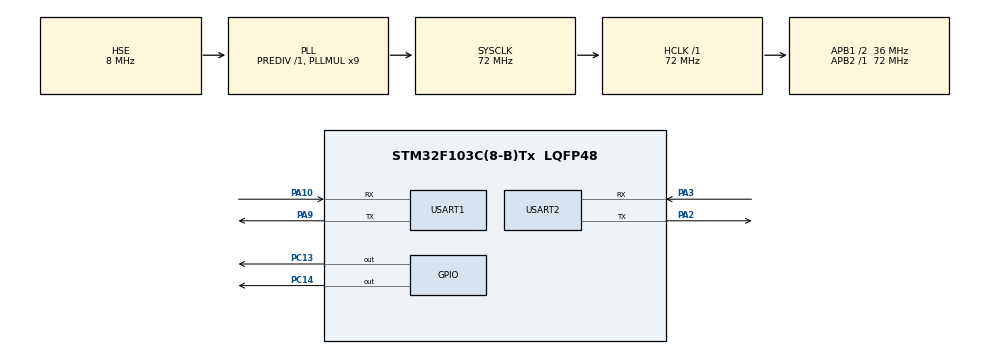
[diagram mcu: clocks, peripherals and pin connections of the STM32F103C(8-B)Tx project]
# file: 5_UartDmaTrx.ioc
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Dma.Request0=USART1_TX
Dma.Request1=USART2_TX
Dma.USART1_TX.0.Direction=DMA_MEMORY_TO_PERIPH
Dma.USART1_TX.0.Instance=DMA1_Channel4
Dma.USART1_TX.0.MemDataAlignment=DMA_MDATAALIGN_BYTE
Dma.USART1_TX.0.MemInc=DMA_MINC_ENABLE
Dma.USART1_TX.0.Mode=DMA_NORMAL
Dma.USART1_TX.0.PeriphDataAlignment=DMA_PDATAALIGN_BYTE
Dma.USART1_TX.0.PeriphInc=DMA_PINC_DISABLE
Dma.USART1_TX.0.Priority=DMA_PRIORITY_MEDIUM
Dma.USART2_TX.1.Direction=DMA_MEMORY_TO_PERIPH
Dma.USART2_TX.1.Instance=DMA1_Channel7
Dma.USART2_TX.1.MemDataAlignment=DMA_MDATAALIGN_BYTE
Dma.USART2_TX.1.MemInc=DMA_MINC_ENABLE
Dma.USART2_TX.1.Mode=DMA_NORMAL
Dma.USART2_TX.1.PeriphDataAlignment=DMA_PDATAALIGN_BYTE
Dma.USART2_TX.1.PeriphInc=DMA_PINC_DISABLE
Dma.USART2_TX.1.Priority=DMA_PRIORITY_MEDIUM
FREERTOS.Tasks01=Task,24,128,Start_Task,Default,NULL,Dynamic,NULL,NULL
Mcu.Family=STM32F1
Mcu.Name=STM32F103C(8-B)Tx
Mcu.Package=LQFP48
NVIC.DMA1_Channel4_IRQn=true\:5\:0\:false\:false\:true\:true\:false\:true\:true
NVIC.DMA1_Channel7_IRQn=true\:5\:0\:false\:false\:true\:true\:false\:true\:true
NVIC.PriorityGroup=NVIC_PRIORITYGROUP_4
NVIC.TIM4_IRQn=true\:15\:0\:false\:false\:true\:false\:false\:true\:true
NVIC.TimeBase=TIM4_IRQn
NVIC.TimeBaseIP=TIM4
NVIC.USART1_IRQn=true\:5\:0\:false\:false\:true\:true\:false\:true\:true
NVIC.USART2_IRQn=true\:5\:0\:false\:false\:true\:true\:true\:true\:true
PA10.Mode=Asynchronous
PA10.Signal=USART1_RX
PA13.Mode=Serial_Wire
PA13.Signal=SYS_JTMS-SWDIO
PA14.Mode=Serial_Wire
PA14.Signal=SYS_JTCK-SWCLK
PA2.Mode=Asynchronous
PA2.Signal=USART2_TX
PA3.Mode=Asynchronous
PA3.Signal=USART2_RX
PA9.Mode=Asynchronous
PA9.Signal=USART1_TX
PC13-TAMPER-RTC.PinState=GPIO_PIN_SET
PC13-TAMPER-RTC.Signal=GPIO_Output
PC14-OSC32_IN.PinState=GPIO_PIN_SET
PC14-OSC32_IN.Signal=GPIO_Output
PD0-OSC_IN.Mode=HSE-External-Oscillator
PD0-OSC_IN.Signal=RCC_OSC_IN
PD1-OSC_OUT.Mode=HSE-External-Oscillator
PD1-OSC_OUT.Signal=RCC_OSC_OUT
ProjectManager.HeapSize=0x200
ProjectManager.StackSize=0x400
ProjectManager.TargetToolchain=MDK-ARM V5.32
RCC.AHBFreq_Value=72000000
RCC.APB1CLKDivider=RCC_HCLK_DIV2
RCC.APB1Freq_Value=36000000
RCC.APB1TimFreq_Value=72000000
RCC.APB2Freq_Value=72000000
RCC.APB2TimFreq_Value=72000000
RCC.EnbaleCSS=true
RCC.HCLKFreq_Value=72000000
RCC.PLLMUL=RCC_PLL_MUL9
RCC.PLLSourceVirtual=RCC_PLLSOURCE_HSE
RCC.SYSCLKFreq_VALUE=72000000
RCC.SYSCLKSource=RCC_SYSCLKSOURCE_PLLCLK
RCC.USBFreq_Value=72000000
USART1.VirtualMode=VM_ASYNC
USART2.VirtualMode=VM_ASYNC
VP_FREERTOS_VS_CMSIS_V2.Mode=CMSIS_V2
VP_SYS_VS_tim4.Mode=TIM4
board=custom

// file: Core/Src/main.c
/* USER CODE BEGIN Header */
/**
  ******************************************************************************
  * @file           : main.c
  * @brief          : Main program body
  ******************************************************************************
  * @attention
  *
  * Copyright (c) 2025 STMicroelectronics.
  * All rights reserved.
  *
  * This software is licensed under terms that can be found in the LICENSE file
  * in the root directory of this software component.
  * If no LICENSE file comes with this software, it is provided AS-IS.
  *
  ******************************************************************************
  */
/* USER CODE END Header */
#include "main.h"
#include "cmsis_os.h"
#include "dma.h"
#include "usart.h"
#include "gpio.h"

/* USER CODE BEGIN PV */

uint8_t tx_buf[64];

/* USER CODE END PV */

void SystemClock_Config(void);
void MX_FREERTOS_Init(void);

int main(void)
{

  /* MCU Configuration--------------------------------------------------------*/

  /* Reset of all peripherals, Initializes the Flash interface and the Systick. */
  HAL_Init();

  /* Configure the system clock */
  SystemClock_Config();

  /* Initialize all configured peripherals */
  MX_GPIO_Init();
  MX_DMA_Init();
  MX_USART1_UART_Init();
  MX_USART2_UART_Init();

  /* Init scheduler */
  osKernelInitialize();  /* Call init function for freertos objects (in cmsis_os2.c) */
  MX_FREERTOS_Init();

  /* Start scheduler */
  osKernelStart();

  /* We should never get here as control is now taken by the scheduler */

  /* Infinite loop */
  while (1)
  {

  }
}

void SystemClock_Config(void)
{
  RCC_OscInitTypeDef RCC_OscInitStruct = {0};
  RCC_ClkInitTypeDef RCC_ClkInitStruct = {0};

  /** Initializes the RCC Oscillators according to the specified parameters
  * in the RCC_OscInitTypeDef structure.
  */
  RCC_OscInitStruct.OscillatorType = RCC_OSCILLATORTYPE_HSE;
  RCC_OscInitStruct.HSEState = RCC_HSE_ON;
  RCC_OscInitStruct.HSEPredivValue = RCC_HSE_PREDIV_DIV1;
  RCC_OscInitStruct.HSIState = RCC_HSI_ON;
  RCC_OscInitStruct.PLL.PLLState = RCC_PLL_ON;
  RCC_OscInitStruct.PLL.PLLSource = RCC_PLLSOURCE_HSE;
  RCC_OscInitStruct.PLL.PLLMUL = RCC_PLL_MUL9;
  if (HAL_RCC_OscConfig(&RCC_OscInitStruct) != HAL_OK)
  {
    Error_Handler();
  }

  /** Initializes the CPU, AHB and APB buses clocks
  */
  RCC_ClkInitStruct.ClockType = RCC_CLOCKTYPE_HCLK|RCC_CLOCKTYPE_SYSCLK
                              |RCC_CLOCKTYPE_PCLK1|RCC_CLOCKTYPE_PCLK2;
  RCC_ClkInitStruct.SYSCLKSource = RCC_SYSCLKSOURCE_PLLCLK;
  RCC_ClkInitStruct.AHBCLKDivider = RCC_SYSCLK_DIV1;
  RCC_ClkInitStruct.APB1CLKDivider = RCC_HCLK_DIV2;
  RCC_ClkInitStruct.APB2CLKDivider = RCC_HCLK_DIV1;

  if (HAL_RCC_ClockConfig(&RCC_ClkInitStruct, FLASH_LATENCY_2) != HAL_OK)
  {
    Error_Handler();
  }

  /** Enables the Clock Security System
  */
  HAL_RCC_EnableCSS();
}

/* USER CODE BEGIN 4 */

void HAL_UART_TxCpltCallback(UART_HandleTypeDef *huart)
{
  if (huart->Instance == USART1)
  {
    HAL_GPIO_TogglePin(GPIOC, GPIO_PIN_13);
  }
  if (huart->Instance == USART2)
  {
    HAL_GPIO_TogglePin(GPIOC, GPIO_PIN_14);
  }
}

/* USER CODE END 4 */

void HAL_TIM_PeriodElapsedCallback(TIM_HandleTypeDef *htim)
{
  if (htim->Instance == TIM4)
  {
    HAL_IncTick();
  }
}

void Error_Handler(void)
{
  __disable_irq();
  while (1)
  {
  }
}

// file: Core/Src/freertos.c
/* USER CODE BEGIN Header */
/**
  ******************************************************************************
  * File Name          : freertos.c
  * Description        : Code for freertos applications
  ******************************************************************************
  * @attention
  *
  * Copyright (c) 2025 STMicroelectronics.
  * All rights reserved.
  *
  * This software is licensed under terms that can be found in the LICENSE file
  * in the root directory of this software component.
  * If no LICENSE file comes with this software, it is provided AS-IS.
  *
  ******************************************************************************
  */
/* USER CODE END Header */

#include "FreeRTOS.h"
#include "task.h"
#include "main.h"
#include "cmsis_os.h"

/* USER CODE BEGIN Includes */

#include "stdio.h"
#include "usart.h"

/* USER CODE END Includes */

/* USER CODE BEGIN Variables */

extern uint8_t tx_buf[64];

/* USER CODE END Variables */
/* Definitions for Task */
osThreadId_t TaskHandle;
const osThreadAttr_t Task_attributes = {
  .name = "Task",
  .stack_size = 128 * 4,
  .priority = (osPriority_t) osPriorityNormal,
};

void Start_Task(void *argument);

void MX_FREERTOS_Init(void); /* (MISRA C 2004 rule 8.1) */

void MX_FREERTOS_Init(void) {

  /* Create the thread(s) */
  /* creation of Task */
  TaskHandle = osThreadNew(Start_Task, NULL, &Task_attributes);

}

void Start_Task(void *argument)
{
  /* USER CODE BEGIN Start_Task */
  /* Infinite loop */
  for(;;)
  {
    int len = sprintf((char *)tx_buf, "Hello FreeRTOS + DMA!\r\n");
    // HAL_UART_Transmit_DMA(&huart2,tx_buf, len);  // 异步发送

    HAL_UART_Transmit_DMA(&huart1, tx_buf, len);  // 异步发送
    // HAL_GPIO_TogglePin(GPIOC, GPIO_PIN_13);

    osDelay(500);
  }
  /* USER CODE END Start_Task */
}
